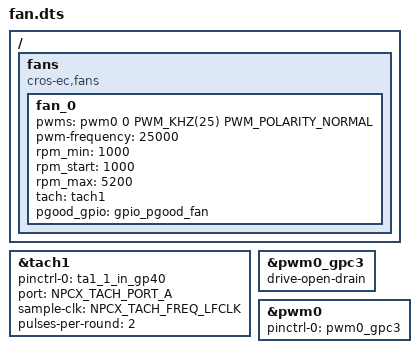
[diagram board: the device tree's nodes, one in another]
/* Copyright 2021 The Chromium OS Authors. All rights reserved.
 * Use of this source code is governed by a BSD-style license that can be
 * found in the LICENSE file.
 */

/ {
	fans {
		compatible = "cros-ec,fans";

		fan_0 {
			pwms = <&pwm0 0 PWM_KHZ(25) PWM_POLARITY_NORMAL>;
			pwm-frequency = <25000>;
			rpm_min = <1000>;
			rpm_start = <1000>;
			rpm_max = <5200>;
			tach = <&tach1>;
			pgood_gpio = <&gpio_pgood_fan>;
		};
	};
};

/* Tachometer for fan speed measurement */
&tach1 {
	status = "okay";
	pinctrl-0 = <&ta1_1_in_gp40>;
	pinctrl-names = "default";
	port = <NPCX_TACH_PORT_A>; /* port-A is selected */
	sample-clk = <NPCX_TACH_FREQ_LFCLK>; /* Use LFCLK as sampling clock */
	pulses-per-round = <2>; /* number of pulses per round of encoder */
};

&pwm0_gpc3 {
	drive-open-drain;
};

&pwm0 {
	status = "okay";
	pinctrl-0 = <&pwm0_gpc3>;
	pinctrl-names = "default";
};
